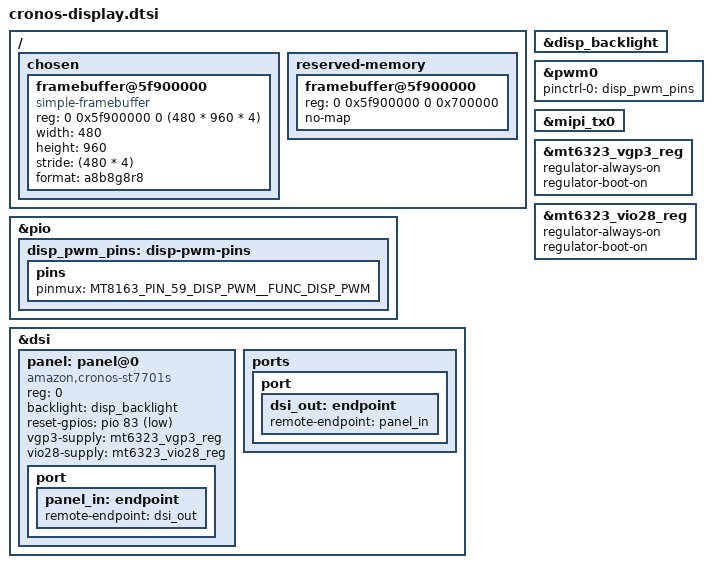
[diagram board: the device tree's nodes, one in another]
// SPDX-License-Identifier: GPL-2.0-only OR MIT
/*
 * TECHO5: the Echo Show 5 (2021) display. The bootloader brings the panel up; like the rook tree the
 * DSI and PHY resets are dropped so the kernel takes it over as it is. Pins from Amazon's cronos.dtsi:
 * panel reset pio 83, backlight PWM pio 59, supplies vgp3 and vio28.
 */

/ {
	chosen {
		#address-cells = <2>;
		#size-cells = <2>;

		/* Describe the bootloader scanout for framebuffer handover to DRM. */
		framebuffer@5f900000 {
			compatible = "simple-framebuffer";
			reg = <0 0x5f900000 0 (480 * 960 * 4)>;
			width = <480>;
			height = <960>;
			stride = <(480 * 4)>;
			format = "a8b8g8r8";
			status = "okay";
		};
	};

	reserved-memory {
		/* Preserve the bootloader's scanout until DRM takes over. */
		framebuffer@5f900000 {
			reg = <0 0x5f900000 0 0x700000>;
			no-map;
		};
	};
};

&disp_backlight {
	/delete-property/ enable-gpios;
};

&pio {
	disp_pwm_pins: disp-pwm-pins {
		pins {
			pinmux = <MT8163_PIN_59_DISP_PWM__FUNC_DISP_PWM>;
		};
	};
};

&pwm0 {
	pinctrl-names = "default";
	pinctrl-0 = <&disp_pwm_pins>;
};

&dsi {
	/delete-property/ resets;
	status = "okay";

	#address-cells = <1>;
	#size-cells = <0>;

	panel: panel@0 {
		compatible = "amazon,cronos-st7701s";
		reg = <0>;
		backlight = <&disp_backlight>;
		reset-gpios = <&pio 83 GPIO_ACTIVE_LOW>;
		vgp3-supply = <&mt6323_vgp3_reg>;
		vio28-supply = <&mt6323_vio28_reg>;

		port {
			panel_in: endpoint {
				remote-endpoint = <&dsi_out>;
			};
		};
	};

	ports {
		#address-cells = <1>;
		#size-cells = <0>;

		port {
			dsi_out: endpoint {
				remote-endpoint = <&panel_in>;
			};
		};
	};
};

&mipi_tx0 {
	/delete-property/ resets;
	status = "okay";
};

&mt6323_vgp3_reg {
	regulator-always-on;
	regulator-boot-on;
};

&mt6323_vio28_reg {
	regulator-always-on;
	regulator-boot-on;
};
